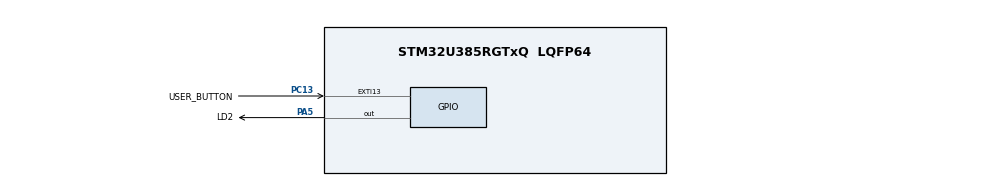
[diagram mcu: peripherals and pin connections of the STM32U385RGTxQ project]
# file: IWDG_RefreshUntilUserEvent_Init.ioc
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CORTEX_M33_NS.userName=CORTEX_M33
IWDG.Prescaler=IWDG_PRESCALER_4
IWDG.Reload=4078
IWDG.Window=4095
Mcu.Family=STM32U3
Mcu.Name=STM32U385RGTxQ
Mcu.Package=LQFP64
NVIC.EXTI13_IRQn=true\:0\:0\:false\:false\:true\:true\:true\:true
NVIC.PriorityGroup=NVIC_PRIORITYGROUP_4
PA5.GPIO_Label=LD2
PA5.GPIO_PuPd=GPIO_NOPULL
PA5.Signal=GPIO_Output
PC13.GPIO_Label=USER_BUTTON
PC13.GPIO_ModeDefaultEXTI=GPIO_MODE_IT_RISING
PC13.GPIO_PuPd=GPIO_PULLDOWN
PC13.Signal=GPXTI13
ProjectManager.HeapSize=0x200
ProjectManager.StackSize=0x400
ProjectManager.TargetToolchain=EWARM V9.20
RCC.ADCFreq_Value=96000000
RCC.AHBFreq_Value=96000000
RCC.APB1Freq_Value=96000000
RCC.APB1TimFreq_Value=96000000
RCC.APB2Freq_Value=96000000
RCC.APB2TimFreq_Value=96000000
RCC.APB3Freq_Value=96000000
RCC.CortexFreq_Value=12000000
RCC.HCLKFreq_Value=96000000
RCC.HSE_VALUE=16000000
RCC.HSI48_VALUE=48000000
RCC.HSI_VALUE=16000000
RCC.LSE_VALUE=32768
RCC.LSIDIV_VALUE=32000
RCC.MSISDIV=RCC_MSI_DIV1
RCC.MSI_VALUE=96000000
RCC.PWR_Regulator_Voltage_Scale=PWR_REGULATOR_VOLTAGE_SCALE1
RCC.SYSCLKFreq_VALUE=96000000
RCC.USBFreq_Value=96000000
VP_ICACHE_VS_ICACHE.Mode=DirectMappedCache
VP_IWDG_VS_IWDG.Mode=IWDG_Activate
VP_PWR_VS_DBSignals.Mode=DisableDeadBatterySignals
VP_PWR_VS_LPOM.Mode=PowerOptimisation
VP_PWR_VS_SECSignals.Mode=Security/Privilege
board=custom

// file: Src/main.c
/* USER CODE BEGIN Header */
/**
  ******************************************************************************
  * @file    Examples_LL/IWDG/IWDG_RefreshUntilUserEvent_Init/Src/main.c
  * @author  MCD Application Team
  * @brief   This example describes how to configure IWDG down-counter (without Window)
  *          using the STM32U3xx IWDG LL API.
  *          Peripheral initialization done using LL unitary services functions.
  ******************************************************************************
  * @attention
  *
  * Copyright (c) 2024 STMicroelectronics.
  * All rights reserved.
  *
  * This software is licensed under terms that can be found in the LICENSE file
  * in the root directory of this software component.
  * If no LICENSE file comes with this software, it is provided AS-IS.
  *
  ******************************************************************************
  */
/* USER CODE END Header */
#include "main.h"

/* USER CODE BEGIN PV */
static __IO uint8_t ubKeyPressed = 0;
/* USER CODE END PV */

void SystemClock_Config(void);
static void MX_GPIO_Init(void);
static void MX_IWDG_Init(void);
static void MX_ICACHE_Init(void);
/* USER CODE BEGIN PFP */
void     Check_IWDG_Reset(void);
void     LED_On(void);
/* USER CODE END PFP */

int main(void)
{

  /* MCU Configuration--------------------------------------------------------*/

  /* Reset of all peripherals, Initializes the Flash interface and the Systick. */

  /* System interrupt init*/
  NVIC_SetPriorityGrouping(NVIC_PRIORITYGROUP_4);

  /* Configure the system clock */
  SystemClock_Config();

  /* USER CODE BEGIN SysInit */

  /* Check if the system has resumed from IWDG reset */
  Check_IWDG_Reset();

  /* USER CODE END SysInit */

  /* Initialize all configured peripherals */
  MX_GPIO_Init();
  MX_IWDG_Init();
  MX_ICACHE_Init();

  /* Infinite loop */
  while (1)
  {

    /* USER CODE BEGIN 3 */

    if (1 != ubKeyPressed)
    {
      /* Refresh IWDG down-counter to default value */
      LL_IWDG_ReloadCounter(IWDG);

      LL_GPIO_TogglePin(LD2_GPIO_Port, LD2_Pin);
      /* Note that period used for Counter Reload MUST be higher than blinking timing value*/
      /* This Counter reload timeout period is a function of this value and the
         clock prescaler. Refer to the datasheet for the timeout information  */
      LL_mDelay(LED_BLINK_FAST);
    }
  }

  /* USER CODE END 3 */
}

void SystemClock_Config(void)
{
  /** Enable Epod Booster
  */
  LL_AHB1_GRP2_EnableClock(LL_AHB1_GRP2_PERIPH_PWR);
  LL_RCC_SetEPODBoosterClkSource(LL_RCC_EPODBOOSTCLKSRCE_MSIS);
  LL_RCC_SetEPODBoosterClkPrescaler(LL_RCC_EPODBOOSTCLKPRESCAL_1);
  LL_PWR_EnableEPODBooster();
  while(LL_PWR_IsActiveFlag_BOOST() != 1U)
  {
  }

  /** Configure the main internal regulator output voltage
  */
  LL_PWR_SetRegulVoltageScaling(LL_PWR_REGU_VOLTAGE_SCALE1);
  while(LL_PWR_GetRegulCurrentVOS() != LL_PWR_REGU_VOLTAGE_SCALE1)
  {
  }

  /** Set Flash latency before switching to MSIS
  */
  LL_FLASH_SetLatency(LL_FLASH_LATENCY_2);
  while(LL_FLASH_GetLatency() != LL_FLASH_LATENCY_2)
  {
  }

  LL_PWR_EnableBkUpAccess();
  while (LL_PWR_IsEnabledBkUpAccess () == 0U)
  {
  }

  LL_RCC_LSI_Enable();

   /* Wait till LSI is ready */
  while(LL_RCC_LSI_IsReady() != 1)
  {
  }

  /* Activate MSIS as source */
  LL_RCC_MSIS_SetClockSource(LL_RCC_MSIS_CLOCK_SOURCE_RC0);
  LL_RCC_MSIS_SetClockDivision(LL_RCC_MSIS_CLOCK_SOURCE_RC_DIV_1);
  LL_RCC_MSI_SetMSIxClockRange();
  LL_RCC_SetSysClkSource(LL_RCC_SYS_CLKSOURCE_MSIS);

   /* Wait till System clock is ready */
  while(LL_RCC_GetSysClkSource() != LL_RCC_SYS_CLKSOURCE_MSIS)
  {
  }

  LL_RCC_SetAHBPrescaler(LL_RCC_HCLK_SYSCLK_DIV_1);
  LL_RCC_SetAPB1Prescaler(LL_RCC_APB1_HCLK_DIV_1);
  LL_RCC_SetAPB2Prescaler(LL_RCC_APB2_HCLK_DIV_1);
  LL_RCC_SetAPB3Prescaler(LL_RCC_APB3_HCLK_DIV_1);

  LL_Init1msTick(96000000);

  LL_SetSystemCoreClock(96000000);
}

static void MX_ICACHE_Init(void)
{

  /** Enable instruction cache in 1-way (direct mapped cache)
  */
  LL_ICACHE_SetMode(LL_ICACHE_1WAY);
  LL_ICACHE_Enable();

}

static void MX_IWDG_Init(void)
{

  LL_IWDG_Enable(IWDG);
  LL_IWDG_EnableWriteAccess(IWDG);
  LL_IWDG_SetPrescaler(IWDG, LL_IWDG_PRESCALER_4);
  LL_IWDG_SetReloadCounter(IWDG, 4078);
  while (LL_IWDG_IsReady(IWDG) != 1)
  {
  }

  LL_IWDG_ReloadCounter(IWDG);

}

static void MX_GPIO_Init(void)
{
  LL_EXTI_InitTypeDef EXTI_InitStruct = {0};
  LL_GPIO_InitTypeDef GPIO_InitStruct = {0};

  /* GPIO Ports Clock Enable */
  LL_AHB2_GRP1_EnableClock(LL_AHB2_GRP1_PERIPH_GPIOC);
  LL_AHB2_GRP1_EnableClock(LL_AHB2_GRP1_PERIPH_GPIOA);

  /**/
  LL_GPIO_ResetOutputPin(LD2_GPIO_Port, LD2_Pin);

  /**/
  LL_EXTI_SetEXTISource(LL_EXTI_CONFIG_PORTC, LL_EXTI_CONFIG_LINE13);

  /**/
  EXTI_InitStruct.Line_0_31 = LL_EXTI_LINE_13;
  EXTI_InitStruct.LineCommand = ENABLE;
  EXTI_InitStruct.Mode = LL_EXTI_MODE_IT;
  EXTI_InitStruct.Trigger = LL_EXTI_TRIGGER_RISING;
  LL_EXTI_Init(&EXTI_InitStruct);

  /**/
  LL_GPIO_SetPinPull(USER_BUTTON_GPIO_Port, USER_BUTTON_Pin, LL_GPIO_PULL_DOWN);

  /**/
  LL_GPIO_SetPinMode(USER_BUTTON_GPIO_Port, USER_BUTTON_Pin, LL_GPIO_MODE_INPUT);

  /**/
  GPIO_InitStruct.Pin = LD2_Pin;
  GPIO_InitStruct.Mode = LL_GPIO_MODE_OUTPUT;
  GPIO_InitStruct.Speed = LL_GPIO_SPEED_FREQ_LOW;
  GPIO_InitStruct.OutputType = LL_GPIO_OUTPUT_PUSHPULL;
  GPIO_InitStruct.Pull = LL_GPIO_PULL_NO;
  LL_GPIO_Init(LD2_GPIO_Port, &GPIO_InitStruct);

  /* EXTI interrupt init*/
  NVIC_SetPriority(EXTI13_IRQn, NVIC_EncodePriority(NVIC_GetPriorityGrouping(),0, 0));
  NVIC_EnableIRQ(EXTI13_IRQn);

}

/* USER CODE BEGIN 4 */

/**
  * @brief  This function check if the system has resumed from IWDG reset
  * @param  None
  * @retval None
  */
void Check_IWDG_Reset(void)
{
  if (LL_RCC_IsActiveFlag_IWDGRST())
  {
    /* clear IWDG reset flag */
    LL_RCC_ClearResetFlags();

    /* Re-Initialize GPIO configured peripheral */
    MX_GPIO_Init();

    /* turn Led on and wait for user event to perform example again */
    LED_On();

    while(ubKeyPressed != 1)
    {
    }

    /* Reset ubKeyPressed value */
    ubKeyPressed = 0;
  }
}

/**
  * @brief  Turn-on LD2.
  * @param  None
  * @retval None
  */
void LED_On(void)
{
  /* Turn LD2 on */
  LL_GPIO_SetOutputPin(LD2_GPIO_Port, LD2_Pin);
}

/******************************************************************************/
/*   USER IRQ HANDLER TREATMENT                                               */
/******************************************************************************/
/**
  * @brief  Function to manage IRQ Handler
  * @param  None
  * @retval None
  */
void UserButton_Callback(void)
{
  ubKeyPressed = 1;
}

/* USER CODE END 4 */

void Error_Handler(void)
{
}

#ifdef  USE_FULL_ASSERT
/**
  * @brief  Reports the name of the source file and the source line number
  *         where the assert_param error has occurred.
  * @param  file: pointer to the source file name
  * @param  line: assert_param error line source number
  * @retval None
  */
void assert_failed(uint8_t *file, uint32_t line)
{
  /* USER CODE BEGIN 6 */
  /* User can add his own implementation to report the file name and line number,
     tex: printf("Wrong parameters value: file %s on line %d\r\n", file, line) */
  /*Infinite Loop */
  while(1)
 {
 }
  /* USER CODE END 6 */
}
#endif /* USE_FULL_ASSERT */
